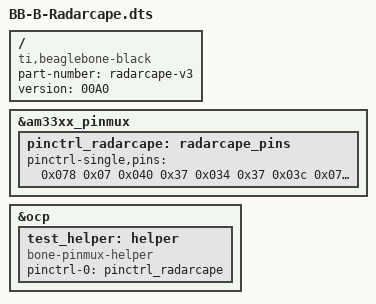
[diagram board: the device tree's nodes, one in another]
/*
 * Copyright (C) 2012 Texas Instruments Incorporated - http://www.ti.com/
 *
 * This program is free software; you can redistribute it and/or modify
 * it under the terms of the GNU General Public License version 2 as
 * published by the Free Software Foundation.
 *
 * Adapted to fit the Radarcape based on the beaglebone black board.
 * Pin definitions were taken from the original Radarcape, by Guenter Koellner.
 */
/dts-v1/;
/plugin/;

/{
    compatible = "ti,beaglebone-black";
    part-number = "radarcape-v3";
    version = "00A0";

    fragment@0 {
        target = <&am33xx_pinmux>;
        __overlay__ {
            pinctrl_radarcape: radarcape_pins {
                pinctrl-single,pins = <
                    /* Watchdog retrigger output */
                    0x078 0x07  /* P9_12 GPIO1_28 #60 Output Mode7 */

                    /* GPS 1PPS Input */
                    0x040 0x37  /* P9_15 GPIO1_16 #48 Input  Mode7 pullup    PPS1 input */

                    /* FPGA Pins */
                    0x034 0x37  /* P8_11 GPIO1_13 #45 Input  Mode7 pullup    CONF_DONE  */
                    0x03c 0x07  /* P8_15 GPIO1_15 #47 Output Mode7           DCLK       */
                    0x038 0x37  /* P8_16 GPIO1_14 #46 Input  Mode7 pullup    nStatus    */
                    0x030 0x07  /* P8_12 GPIO1_12 #44 Output Mode7           DATA0      */
                    0x07c 0x07  /* P8_26 GPIO1_29 #61 Output Mode7           nCONF      */

                    /* UART5 CTS/RTS as addon to the default UART5 device tree settings */
                    0x0d8 0x36  /* P8_31 UART5_CTSN   Input  Mode6 pullup    CTS input  */
                    0x0dc 0x06  /* P8_32 UART5_RTSN   Output Mode6 no pull   RTS output */
                >;
            };
        };
    };

    fragment@1 {
        target = <&ocp>;
        __overlay__ {
            test_helper: helper {
                compatible = "bone-pinmux-helper";
                pinctrl-names = "default";
                pinctrl-0 = <&pinctrl_radarcape>;
                status = "okay";
            };
        };
    };
};

